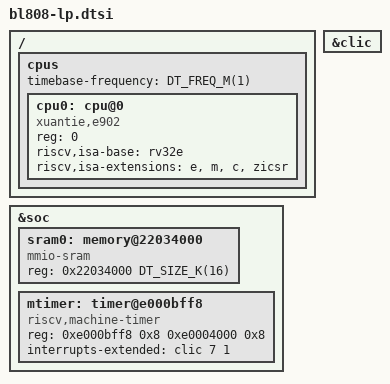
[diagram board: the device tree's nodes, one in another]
/*
 * Copyright The Zephyr Project Contributors
 *
 * SPDX-License-Identifier: Apache-2.0
 *
 * BL808 LP core (T-Head E902, RV32EMC).
 * Uses the CLIC defined in bl808.dtsi (shared with M0).
 */

#include <bflb/bl808.dtsi>

/ {
	cpus {
		#address-cells = <1>;
		#size-cells = <0>;
		timebase-frequency = <DT_FREQ_M(1)>;

		cpu0: cpu@0 {
			device_type = "cpu";
			compatible = "xuantie,e902", "riscv";
			reg = <0>;
			riscv,isa-base = "rv32e";
			riscv,isa-extensions = "e", "m", "c", "zicsr";
			status = "okay";
		};
	};
};

&soc {
	sram0: memory@22034000 {
		compatible = "mmio-sram";
		reg = <0x22034000 DT_SIZE_K(16)>;
	};

	mtimer: timer@e000bff8 {
		compatible = "riscv,machine-timer";
		reg = <0xe000bff8 0x8 0xe0004000 0x8>;
		reg-names = "mtime", "mtimecmp";
		interrupts-extended = <&clic 7 1>;
	};
};

&clic {
	status = "okay";
};
